VERSION ""

NS_ :

BS_:

BU_: CCU BDC MOOD_LP SEAT_UNIT LAMP_UNIT CLUSTER MFSW FrontConsoleSwitch BCM
VAL_TABLE_ vtbSensorReqCause 15 "SNA" 2 "by Request 2" 1 "by Request 1" 0 "normal cycle" ;
VAL_TABLE_ vtbErrorDescription 255 "ERROR" ;

BO_ 2015 msg_broad_diag_request: 8 CCU
 SG_ sig_broad_diag_request : 0|64@1+ (1,0) [0|0] ""  BCM,BDC,CLUSTER,FrontConsoleSwitch,LAMP_UNIT,MFSW,MOOD_LP,SEAT_UNIT

BO_ 1886 msg_bdc_diag_response: 8 BDC
 SG_ sig_bdc_diag_response : 0|64@1+ (1,0) [0|0] ""  CCU

BO_ 1878 msg_bdc_diag_request: 8 CCU
 SG_ sig_bdc_diag_request : 0|64@1+ (1,0) [0|0] ""  BDC

BO_ 1885 msg_mood_diag_response: 8 MOOD_LP
 SG_ sig_mood_diag_response : 0|64@1+ (1,0) [0|0] ""  CCU

BO_ 1877 msg_mood_diag_request: 8 CCU
 SG_ sig_mood_diag_request : 0|64@1+ (1,0) [0|0] ""  MOOD_LP

BO_ 1884 msg_seat_unit_diag_response: 8 SEAT_UNIT
 SG_ sig_seat_unit_diag_response : 0|64@1- (1,0) [0|0] ""  CCU

BO_ 1876 msg_seat_unit_diag_request: 8 CCU
 SG_ sig_seat_unit_diag_request : 0|64@1+ (1,0) [0|0] ""  SEAT_UNIT

BO_ 1883 msg_lamp_unit_diag_response: 8 LAMP_UNIT
 SG_ sig_lamp_unit_diag_response : 0|64@1+ (1,0) [0|0] ""  CCU

BO_ 1875 msg_lamp_unit_diag_request: 8 CCU
 SG_ sig_lamp_unit_diag_request : 0|64@1+ (1,0) [0|0] ""  LAMP_UNIT

BO_ 1882 msg_cluster_diag_response: 8 CLUSTER
 SG_ sig_cluster_diag_response : 0|64@1+ (1,0) [0|0] ""  CCU

BO_ 1874 msg_cluster_diag_request: 8 CCU
 SG_ sig_cluster_diag_request : 0|64@1+ (1,0) [0|0] ""  CLUSTER

BO_ 1881 msg_mfsw_diag_response: 8 MFSW
 SG_ sig_mfsw_diag_response : 0|64@1+ (1,0) [0|0] ""  CCU

BO_ 1873 msg_mfsw_diag_request: 8 CCU
 SG_ sig_mfsw_diag_request : 0|64@1+ (1,0) [0|0] ""  MFSW

BO_ 1880 msg_fconsole_diag_response: 8 FrontConsoleSwitch
 SG_ sig_fconsole_diag_response : 0|64@1+ (1,0) [0|0] ""  CCU

BO_ 1872 msg_fconsole_diag_request: 8 CCU
 SG_ sig_fconsole_diag_request : 0|64@1+ (1,0) [0|0] ""  FrontConsoleSwitch

BO_ 1871 msg_bcm_diag_response: 8 BCM
 SG_ sig_bcm_diag_response : 0|64@1+ (1,0) [0|0] ""  CCU

BO_ 1863 msg_bcm_diag_request: 8 CCU
 SG_ sig_bcm_diag_request : 0|64@1+ (1,0) [0|0] ""  BCM

BO_ 1061 msg_fconsole_cruise: 1 FrontConsoleSwitch
 SG_ sig_cruise_state : 0|1@1+ (1,0) [0|1] ""  CLUSTER,BDC,CCU

BO_ 529 msg_adas_ieb: 1 CCU
 SG_ sig_adas_ieb_cmd : 0|1@1+ (1,0) [0|1] ""  CLUSTER

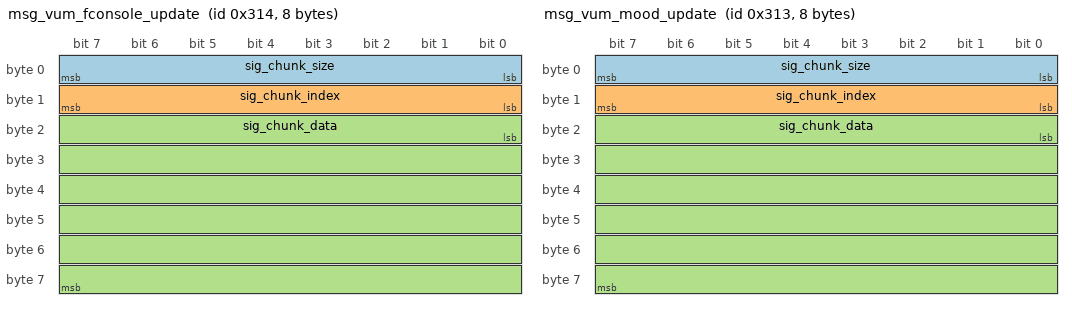
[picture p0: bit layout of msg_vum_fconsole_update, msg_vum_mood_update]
BO_ 788 msg_vum_fconsole_update: 8 CCU
 SG_ sig_chunk_size : 0|8@1+ (1,0) [0|255] ""  FrontConsoleSwitch
 SG_ sig_chunk_index : 8|8@1+ (1,0) [0|255] ""  FrontConsoleSwitch
 SG_ sig_chunk_data : 16|48@1+ (1,0) [0|281474976710655] ""  FrontConsoleSwitch

BO_ 787 msg_vum_mood_update: 8 CCU
 SG_ sig_chunk_size : 0|8@1+ (1,0) [0|255] ""  MOOD_LP
 SG_ sig_chunk_index : 8|8@1+ (1,0) [0|255] ""  MOOD_LP
 SG_ sig_chunk_data : 16|48@1+ (1,0) [0|281474976710655] ""  MOOD_LP

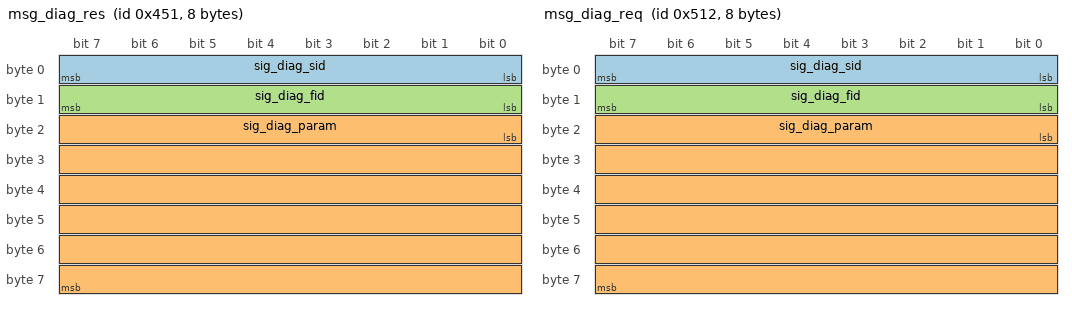
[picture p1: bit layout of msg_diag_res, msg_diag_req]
BO_ 1105 msg_diag_res: 8 LAMP_UNIT
 SG_ sig_diag_sid : 0|8@1+ (1,0) [0|255] ""  CCU
 SG_ sig_diag_param : 16|48@1+ (1,0) [0|281474976710655] ""  CCU
 SG_ sig_diag_fid : 8|8@1+ (1,0) [0|255] ""  CCU

BO_ 1298 msg_diag_req: 8 CCU
 SG_ sig_diag_sid : 0|8@1+ (1,0) [0|255] ""  LAMP_UNIT
 SG_ sig_diag_param : 16|48@1+ (1,0) [0|281474976710655] ""  LAMP_UNIT
 SG_ sig_diag_fid : 8|8@1+ (1,0) [0|255] ""  LAMP_UNIT

BO_ 785 msg_vum_check_update: 2 CCU
 SG_ sig_check_status : 8|4@1+ (1,0) [0|15] ""  MOOD_LP
 SG_ sig_target_ecu : 0|8@1+ (1,0) [0|255] ""  MOOD_LP

BO_ 273 msg_ieb_brake: 1 CCU
 SG_ sig_ieb_brake : 0|1@1+ (1,0) [0|1] ""  FrontConsoleSwitch,LAMP_UNIT

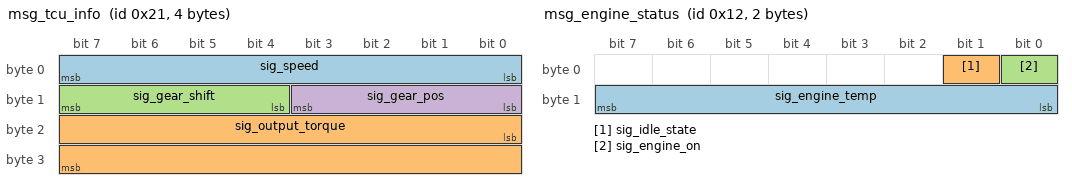
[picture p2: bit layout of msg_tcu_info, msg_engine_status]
BO_ 33 msg_tcu_info: 4 CCU
 SG_ sig_speed : 0|8@1+ (1,0) [0|255] "" Vector__XXX
 SG_ sig_output_torque : 16|16@1- (1,0) [-32768|32767] ""  CLUSTER
 SG_ sig_gear_shift : 12|4@1+ (1,0) [0|15] ""  CLUSTER
 SG_ sig_gear_pos : 8|4@1+ (1,0) [0|15] ""  CLUSTER

BO_ 18 msg_engine_status: 2 CCU
 SG_ sig_engine_temp : 8|8@1+ (1,0) [0|255] ""  CLUSTER
 SG_ sig_idle_state : 1|1@1+ (1,0) [0|1] ""  CLUSTER
 SG_ sig_engine_on : 0|1@1+ (1,0) [0|1] ""  CLUSTER

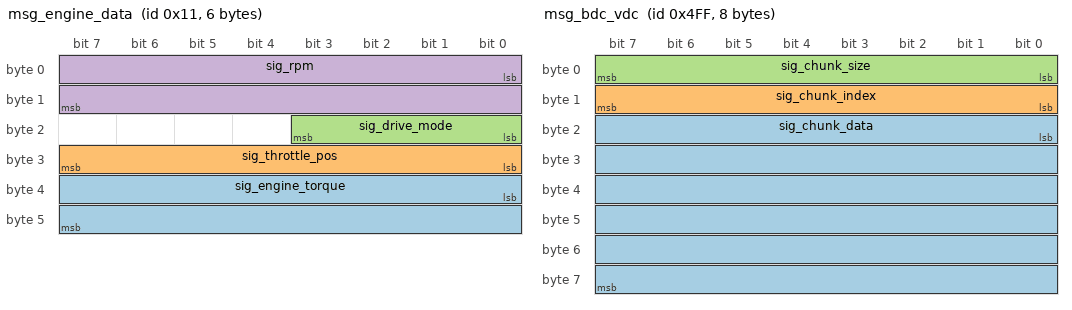
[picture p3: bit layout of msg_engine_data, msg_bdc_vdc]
BO_ 17 msg_engine_data: 6 CCU
 SG_ sig_engine_torque : 32|16@1- (1,0) [-32768|32767] ""  CLUSTER
 SG_ sig_throttle_pos : 24|8@1+ (1,0) [0|255] ""  CLUSTER
 SG_ sig_drive_mode : 16|4@1+ (1,0) [0|15] ""  CLUSTER
 SG_ sig_rpm : 0|16@1+ (1,0) [0|65535] ""  CLUSTER

BO_ 1279 msg_bdc_vdc: 8 BDC
 SG_ sig_chunk_data : 16|48@1+ (1,0) [0|281474976710655] ""  CCU
 SG_ sig_chunk_index : 8|8@1+ (1,0) [0|255] ""  CCU
 SG_ sig_chunk_size : 0|8@1+ (1,0) [0|255] ""  CCU

BO_ 1151 msg_mood_alive: 1 MOOD_LP
 SG_ sig_mood_alive : 0|1@1+ (1,0) [0|1] ""  BDC

BO_ 1150 msg_mood_bdc: 4 MOOD_LP
 SG_ sig_mood_dtc : 0|32@1+ (1,0) [0|4294967295] ""  BDC

BO_ 1137 msg_mood_can_vum: 1 MOOD_LP
 SG_ sig_mood_can_vum : 0|1@1+ (1,0) [0|1] ""  CCU,BDC

BO_ 1135 msg_seat_alive: 1 SEAT_UNIT
 SG_ sig_seat_alive : 0|1@1+ (1,0) [0|1] ""  BDC

BO_ 1134 msg_seat_bdc: 4 SEAT_UNIT
 SG_ sig_seat_dtc : 0|32@1+ (1,0) [0|4294967295] ""  BDC

BO_ 1119 msg_lamp_alive: 1 LAMP_UNIT
 SG_ sig_lamp_alive : 0|1@1+ (1,0) [0|1] ""  BDC

BO_ 1118 msg_lamp_bdc: 4 LAMP_UNIT
 SG_ sig_lamp_dtc : 0|32@1+ (1,0) [0|4294967295] ""  BDC

BO_ 1103 msg_cluster_alive: 1 CLUSTER
 SG_ sig_cluster_alive : 0|1@1+ (1,0) [0|1] ""  BDC

BO_ 1102 msg_cluster_bdc: 4 CLUSTER
 SG_ sig_cluster_dtc : 0|32@1+ (1,0) [0|4294967295] ""  BDC

BO_ 1087 msg_mfsw_alive: 1 MFSW
 SG_ sig_mfsw_alive : 0|1@1+ (1,0) [0|1] ""  BDC

BO_ 1086 msg_mfsw_bdc: 4 MFSW
 SG_ sig_mfsw_dtc : 0|32@1+ (1,0) [0|4294967295] ""  BDC

BO_ 1073 msg_mfsw_status: 1 MFSW
 SG_ sig_cruise_state : 0|1@1+ (1,0) [0|1] ""  BDC,CCU,CLUSTER

BO_ 1071 msg_fconsole_alive: 1 FrontConsoleSwitch
 SG_ sig_fconsole_alive : 0|1@1+ (1,0) [0|1] ""  BDC

BO_ 1070 msg_fconsole_bdc: 4 FrontConsoleSwitch
 SG_ sig_fconsole_dtc : 0|32@1+ (1,0) [0|4294967295] ""  BDC

BO_ 1064 msg_fconsole_can_vum: 1 FrontConsoleSwitch
 SG_ sig_fconsole_can_vum : 0|1@1+ (1,0) [0|1] ""  FrontConsoleSwitch,BDC

BO_ 1060 msg_fconsole_ambient: 1 FrontConsoleSwitch
 SG_ sig_console_ambient_light : 0|8@1+ (1,0) [0|255] ""  BDC,MOOD_LP

BO_ 1058 msg_fconsole_drive: 1 FrontConsoleSwitch
 SG_ sig_console_drive_mode : 0|4@1+ (1,0) [0|15] ""  BDC,CCU

BO_ 1057 msg_fconsole_parking: 1 FrontConsoleSwitch
 SG_ sig_console_parking_brake : 0|1@1+ (1,0) [0|1] ""  BDC,CCU,CLUSTER

BO_ 1055 msg_bcm_alive: 1 BCM
 SG_ sig_bcm_alive : 0|1@1+ (1,0) [0|1] ""  BDC

BO_ 1054 msg_bcm_bdc: 4 BCM
 SG_ sig_bcm_dtc : 0|32@1+ (1,0) [0|4294967295] ""  BDC

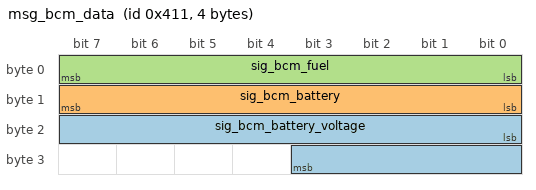
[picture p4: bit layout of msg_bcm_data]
BO_ 1041 msg_bcm_data: 4 BCM
 SG_ sig_bcm_battery_voltage : 16|12@1+ (1,0) [0|4095] ""  BDC,CCU,CLUSTER
 SG_ sig_bcm_battery : 8|8@1+ (1,0) [0|255] ""  BDC,CCU,CLUSTER
 SG_ sig_bcm_fuel : 0|8@1+ (1,0) [0|255] ""  BDC,CCU,CLUSTER

BA_DEF_  "DatabaseVersion" STRING ;
BA_DEF_  "Manufacturer" STRING ;
BA_DEF_ BU_  "NodeLayerModules" STRING ;
BA_DEF_  "BusType" STRING ;
BA_DEF_ SG_  "GenSigSendType" ENUM  "Cyclic","OnWrite","OnWriteWithRepetition","OnChange","OnChangeWithRepetition","IfActive","IfActiveWithRepetition","NoSigSendType","NotUsed","NotUsed","NotUsed","NotUsed","NotUsed";
BA_DEF_ BO_  "GenMsgSendType" ENUM  "Cyclic","NotUsed","NotUsed","NotUsed","NotUsed","Cyclic","NotUsed","IfActive","NoMsgSendType","NotUsed","vector_leerstring";
BA_DEF_ BO_  "GenMsgCycleTime" INT 0 50000;
BA_DEF_ BO_  "GenMsgCycleTimeFast" INT 0 50000;
BA_DEF_ BO_  "GenMsgILSupport" ENUM  "No","Yes";
BA_DEF_DEF_  "DatabaseVersion" "";
BA_DEF_DEF_  "Manufacturer" "Vector";
BA_DEF_DEF_  "NodeLayerModules" "CANoeILNLVector.dll";
BA_DEF_DEF_  "BusType" "CAN";
BA_DEF_DEF_  "GenSigSendType" "Cyclic";
BA_DEF_DEF_  "GenMsgSendType" "NoMsgSendType";
BA_DEF_DEF_  "GenMsgCycleTime" 200;
BA_DEF_DEF_  "GenMsgCycleTimeFast" 20;
BA_DEF_DEF_  "GenMsgILSupport" "Yes";
BA_ "DatabaseVersion" "1.1";
